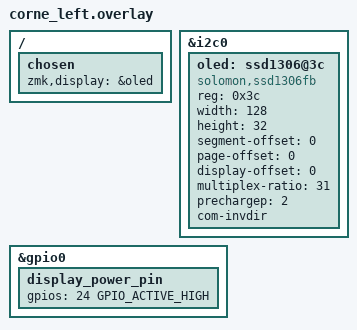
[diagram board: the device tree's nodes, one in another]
#error "CORNE OVERLAY LOADED"
/*
 * Corne v4 – I2C SSD1306 OLED (nice!display adapter)
 * Verified for ZMK 2025/2026
 */

/ {
    chosen {
        zmk,display = &oled;
    };
};

/* Enable I2C bus used by Corne v4 */
&i2c0 {
    status = "okay";

    oled: ssd1306@3c {
        compatible = "solomon,ssd1306fb";
        reg = <0x3c>;

        /* Match common Corne OLED */
        width = <128>;
        height = <32>;        /* change to 64 if your OLED is 128x64 */

        segment-offset = <0>;
        page-offset = <0>;
        display-offset = <0>;
        multiplex-ratio = <31>;

        prechargep = <2>;
        com-invdir;
    };
};

/*
 * Display power control
 * Corne v4 adapter uses a GPIO-controlled VCC
 * GPIO0 pin number MUST match your PCB (24 is standard)
 */
&gpio0 {
    display_power_pin: display_power_pin {
        gpios = <24 GPIO_ACTIVE_HIGH>;
    };
};
